# bao1x_peri register map
Vendor: baochip
Registers are 32-bit, read-write, reset 0x0 unless marked. A register's access mark holds for its fields unless they carry their own. Offsets are from the block's base; [hi:lo] are bit positions; {n}, {i} and the like mark numbered series; <NAME> marks a mode.

## MDMA
Base 0x40012000
{0x0+4i} SFR_EVSEL_CR_EVSEL{i} (i=0..7) — See `mdma.sv#L102 <https://github.com/baochip/baochip-1x/blob/main/rtl/modules/c ore/rtl/mdma.sv#L102>`__ (line numbers are approximate)
  [7:0] cr_evsel{i} — cr_evsel read/write control register
{0x20+4i} SFR_CR_CR_MDMAREQ{i} (i=0..7) — See `mdma.sv#L103 <https://github.com/baochip/baochip-1x/blob/main/rtl/modules/c ore/rtl/mdma.sv#L103>`__ (line numbers are approximate)
  [4:0] cr_mdmareq{i} — cr_mdmareq read/write control register
{0x40+4i} SFR_SR_SR_MDMAREQ{i} (i=0..7) — See `mdma.sv#L104 <https://github.com/baochip/baochip-1x/blob/main/rtl/modules/c ore/rtl/mdma.sv#L104>`__ (line numbers are approximate)
  [4:0] sr_mdmareq{i} — sr_mdmareq read only status register

## QFC
Base 0x40010000
0x00 SFR_IO — See `qfc.sv#L189 <https://github.com/baochip/baochip-1x/blob/main/rtl/modules/co re/rtl/qfc.sv#L189>`__ (line numbers are approximate)
  [7:0] sfr_io — sfr_io read/write control register
0x04 SFR_AR — See `qfc.sv#L190 <https://github.com/baochip/baochip-1x/blob/main/rtl/modules/co re/rtl/qfc.sv#L190>`__ (line numbers are approximate)
  [31:0] sfr_ar — sfr_ar performs action on write of value: 0x5a
0x08 SFR_IODRV — See `qfc.sv#L191 <https://github.com/baochip/baochip-1x/blob/main/rtl/modules/co re/rtl/qfc.sv#L191>`__ (line numbers are approximate)
  [11:0] paddrvsel — paddrvsel read/write control register
0x10 CR_XIP_ADDRMODE — See `qfc.sv#L193 <https://github.com/baochip/baochip-1x/blob/main/rtl/modules/co re/rtl/qfc.sv#L193>`__ (line numbers are approximate)
  [1:0] cr_xip_addrmode — cr_xip_addrmode read/write control register
0x14 CR_XIP_OPCODE — See `qfc.sv#L194 <https://github.com/baochip/baochip-1x/blob/main/rtl/modules/co re/rtl/qfc.sv#L194>`__ (line numbers are approximate)
  [31:0] cr_xip_opcode — cr_xip_opcode read/write control register
0x18 CR_XIP_WIDTH — See `qfc.sv#L195 <https://github.com/baochip/baochip-1x/blob/main/rtl/modules/co re/rtl/qfc.sv#L195>`__ (line numbers are approximate)
  [5:0] cr_xip_width — cr_xip_width read/write control register
0x1C CR_XIP_SSEL — See `qfc.sv#L196 <https://github.com/baochip/baochip-1x/blob/main/rtl/modules/co re/rtl/qfc.sv#L196>`__ (line numbers are approximate)
  [6:0] cr_xip_ssel — cr_xip_ssel read/write control register
0x20 CR_XIP_DUMCYC — See `qfc.sv#L197 <https://github.com/baochip/baochip-1x/blob/main/rtl/modules/co re/rtl/qfc.sv#L197>`__ (line numbers are approximate)
  [15:0] cr_xip_dumcyc — cr_xip_dumcyc read/write control register
0x24 CR_XIP_CFG — See `qfc.sv#L198 <https://github.com/baochip/baochip-1x/blob/main/rtl/modules/co re/rtl/qfc.sv#L198>`__ (line numbers are approximate)
  [14:0] cr_xip_cfg — cr_xip_cfg read/write control register
{0x40+4i} CR_AESKEY_AESKEYIN{i} (i=0..3) — See `qfc.sv#L200 <https://github.com/baochip/baochip-1x/blob/main/rtl/modules/co re/rtl/qfc.sv#L200>`__ (line numbers are approximate)
  [31:0] aeskeyin{i} — cr_aeskey read/write control register
0x50 CR_AESENA — See `qfc.sv#L201 <https://github.com/baochip/baochip-1x/blob/main/rtl/modules/co re/rtl/qfc.sv#L201>`__ (line numbers are approximate)
  [0] cr_aesena — cr_aesena read/write control register

## MBOX_APB
Base 0x40013000
0x00 SFR_WDATA — See `mbox_v0.1.sv#L105 <https://github.com/baochip/baochip-1x/blob/main/rtl/modu les/vexriscv/lib/mbox_v0.1.sv#L105>`__ (line numbers are approximate)
  [31:0] sfr_wdata — sfr_wdata read/write control register
0x04 SFR_RDATA — See `mbox_v0.1.sv#L106 <https://github.com/baochip/baochip-1x/blob/main/rtl/modu les/vexriscv/lib/mbox_v0.1.sv#L106>`__ (line numbers are approximate)
  [31:0] sfr_rdata — sfr_rdata read only status register
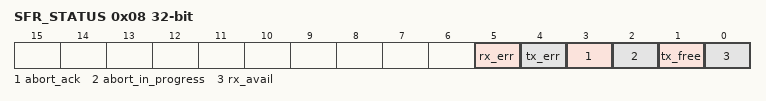
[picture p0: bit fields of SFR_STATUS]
0x08 SFR_STATUS — See `mbox_v0.1.sv#L107 <https://github.com/baochip/baochip-1x/blob/main/rtl/modu les/vexriscv/lib/mbox_v0.1.sv#L107>`__ (line numbers are approximate)
  [5] rx_err — rx_err read only status register
  [4] tx_err — tx_err read only status register
  [3] abort_ack — abort_ack read only status register
  [2] abort_in_progress — abort_in_progress read only status register
  [1] tx_free — tx_free read only status register
  [0] rx_avail — rx_avail read only status register
0x18 SFR_ABORT — See `mbox_v0.1.sv#L108 <https://github.com/baochip/baochip-1x/blob/main/rtl/modu les/vexriscv/lib/mbox_v0.1.sv#L108>`__ (line numbers are approximate)
  [31:0] sfr_abort — sfr_abort performs action on write of value: 0x1
0x1C SFR_DONE — See `mbox_v0.1.sv#L109 <https://github.com/baochip/baochip-1x/blob/main/rtl/modu les/vexriscv/lib/mbox_v0.1.sv#L109>`__ (line numbers are approximate)
  [31:0] sfr_done — sfr_done performs action on write of value: 0x1
